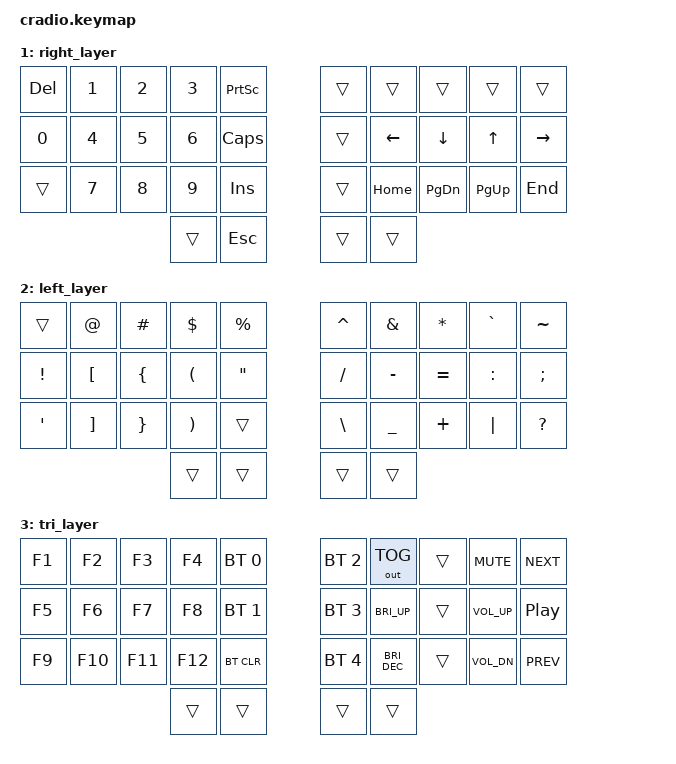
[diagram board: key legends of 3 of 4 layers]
// Copyright (c) 2022 The ZMK Contributors
// SPDX-License-Identifier: MIT

#include <behaviors.dtsi>
#include <dt-bindings/zmk/keys.h>
#include <dt-bindings/zmk/bt.h>
#include <dt-bindings/zmk/outputs.h>

// Home row mods macro
#define HRML(k2,k3,k4) &ht LALT k2  &ht LCTRL k3  &ht LGUI k4
#define HRMR(k1,k2,k3) &ht RGUI k1  &ht RCTRL k2  &ht RALT k3
#define WHRML(k2,k3,k4,k5) &ht LSHFT k2  &ht LALT k3  &ht LCTRL k4 &ht LGUI k5
#define WHRMR(k1,k2,k3,k4) &ht RGUI k1 &ht RCTRL k2  &ht RALT k3  &ht RSHFT k4

#define WIN 0
#define RIG 1
#define LEF 2
#define TRI 3

/* &kscan0 { */
/*     input-gpios */
/*         = <&gpio0 6  (GPIO_ACTIVE_LOW | GPIO_PULL_UP)> */
/*         , <&gpio0 20 (GPIO_ACTIVE_LOW | GPIO_PULL_UP)> */
/*         , <&gpio1 0  (GPIO_ACTIVE_LOW | GPIO_PULL_UP)> */
/*         , <&gpio1 13 (GPIO_ACTIVE_LOW | GPIO_PULL_UP)> */
/*         , <&gpio0 31 (GPIO_ACTIVE_LOW | GPIO_PULL_UP)> */
/*         , <&gpio0 8  (GPIO_ACTIVE_LOW | GPIO_PULL_UP)> */
/*         , <&gpio0 22 (GPIO_ACTIVE_LOW | GPIO_PULL_UP)> */
/*         , <&gpio1 4  (GPIO_ACTIVE_LOW | GPIO_PULL_UP)> */
/*         , <&gpio1 15 (GPIO_ACTIVE_LOW | GPIO_PULL_UP)> */
/*         , <&gpio0 4  (GPIO_ACTIVE_LOW | GPIO_PULL_UP)> */
/*         , <&gpio0 17 (GPIO_ACTIVE_LOW | GPIO_PULL_UP)> */
/*         , <&gpio0 24 (GPIO_ACTIVE_LOW | GPIO_PULL_UP)> */
/*         , <&gpio1 6  (GPIO_ACTIVE_LOW | GPIO_PULL_UP)> */
/*         , <&gpio0 2  (GPIO_ACTIVE_LOW | GPIO_PULL_UP)> */
/*         , <&gpio0 5  (GPIO_ACTIVE_LOW | GPIO_PULL_UP)> */
/*         , <&gpio0 26 (GPIO_ACTIVE_LOW | GPIO_PULL_UP)> */
/*         , <&gpio0 27 (GPIO_ACTIVE_LOW | GPIO_PULL_UP)> */
/*         ; */
/* }; */

/ {
    behaviors {
        ht: hold_tap {
            label = "hold_tap";
            compatible = "zmk,behavior-hold-tap";
            #binding-cells = <2>;
            flavor = "tap-preferred";
            tapping-term-ms = <220>;
            quick-tap-ms = <150>;
            global-quick-tap;
            bindings = <&kp>, <&kp>;
        };
    };

    conditional_layers {
        compatible = "zmk,conditional-layers";
        tri_layer {
            if-layers = <RIG LEF>;
            then-layer = <TRI>;
        };
    };

    keymap {
        compatible = "zmk,keymap";
        default_layer {
            bindings = <
        //╭──────────┬──────────┬──────────┬──────────┬──────────╮   ╭──────────┬──────────┬──────────┬──────────┬──────────╮
        //│  Q       │  W       │  F       │  P       │  B       │   │  J       │  L       │  U       │  Y       │  ;       │
            &kp Q      &kp W      &kp F      &kp P      &kp B          &kp J      &kp L      &kp U      &kp Y      &kp SEMI
        //├──────────┼──────────┼──────────┼──────────┼──────────┤   ├──────────┼──────────┼──────────┼──────────┼──────────┤
        //│  A       │  R (SHFT)│  S (ALT) │  T (CTRL)│  G (WIN) │   │  M (WIN) │  N (CTRL)│  E (ALT) │  I (SHFT)|  O       │
         &kp A    WHRML(R,         S,         T,         G)       WHRMR(M,         N,         E,         I)     &kp O
        //├──────────┼──────────┼──────────┼──────────┼──────────┤   ├──────────┼──────────┼──────────┼──────────┼──────────┤
        //│  Z       │  X       │  C       │  D       │  V       │   │  K       │  H       │ , <      │ . >      │ /        │
            &kp Z      &kp X      &kp C      &kp D      &kp V          &kp K      &kp H      &kp COMMA  &kp DOT    &kp FSLH
        //╰──────────┴──────────┴──────────┼──────────┼──────────┤   ├──────────┼──────────┼──────────┴──────────┴──────────╯
                                            &kp TAB  &lt LEF SPACE   &lt RIG BSPC &kp ENTER
        //                                 ╰──────────┴──────────╯   ╰──────────┴──────────╯
            >;
        };

        right_layer {
            bindings = <
        //╭──────────┬──────────┬──────────┬──────────┬──────────╮   ╭──────────┬──────────┬──────────┬──────────┬──────────╮
        //│   DEL    │  1       │  2       │  3       │  PRTSCR  │   │          │          │          │          │          │
            &kp DEL    &kp N1     &kp N2     &kp N3     &kp PSCRN       &trans     &trans     &trans     &trans    &trans
        //├──────────┼──────────┼──────────┼──────────┼──────────┤   ├──────────┼──────────┼──────────┼──────────┼──────────┤
        //│    0     │ 4        │ 5        │ 6        │   CAPS   |   |          │ LEFT     │ DOWN     │ UP       │ RIGHT    │
            &kp N0     &kp N4     &kp N5     &kp N6     &kp CAPS        &trans    &kp LEFT   &kp DOWN   &kp UP     &kp RIGHT 
        //├──────────┼──────────┼──────────┼──────────┼──────────┤   ├──────────┼──────────┼──────────┼──────────┼──────────┤
        //│          │ 9        │ 8        │ 7        │  INSERT  │   │          │ HOME     │ PAGE DN  │ PAGE UP  │ END      │
            &trans     &kp N7     &kp N8     &kp N9      &kp INS        &trans    &kp HOME   &kp PG_DN  &kp PG_UP  &kp END 
        //╰──────────┴──────────┴──────────┼──────────┼──────────┤   ├──────────┼──────────┼──────────┴──────────┴──────────╯
                                              &trans     &kp ESC        &trans     &trans
        //                                 ╰──────────┴──────────╯   ╰──────────┴──────────╯
            >;
        };

        left_layer {
            bindings = <
        //╭──────────┬──────────┬──────────┬──────────┬──────────╮   ╭──────────┬──────────┬──────────┬──────────┬──────────╮
        //│          │  @       │  #       │  $       │  %       │   │  ^       │  &       │  *       │  `       │  ~       │
            &trans   &kp AT     &kp HASH   &kp DLLR   &kp PRCNT      &kp CARET  &kp AMPS   &kp ASTRK  &kp GRAVE   &kp TILDE
        //├──────────┼──────────┼──────────┼──────────┼──────────┤   ├──────────┼──────────┼──────────┼──────────┼──────────┤
        //│  !       │  [       │  {       │  (       │  "       │   │   /      │  -       │  =       │     :    │  ;       │
            &kp EXCL  &kp LBKT   &kp LBRC   &kp LPAR      &kp DQT     &kp FSLH   &kp MINUS  &kp EQUAL  &kp COLON &kp SEMICOLON
        //├──────────┼──────────┼──────────┼──────────┼──────────┤   ├──────────┼──────────┼──────────┼──────────┼──────────┤
        //│  '       │  ]       │  }       │  )       │          │   │    \     │  _       │  +       │  │       │   ?      │
            &kp SQT     &kp RBKT   &kp RBRC   &kp RPAR   &trans         &kp BSLH   &kp UNDER  &kp PLUS   &kp PIPE  &kp QMARK
        //╰──────────┴──────────┴──────────┼──────────┼──────────┤   ├──────────┼──────────┼──────────┴──────────┴──────────╯
                                             &trans     &trans         &trans     &trans
        //                                 ╰──────────┴──────────╯   ╰──────────┴──────────╯
            >;
        };

        tri_layer {
            bindings = <
        //╭──────────┬──────────┬──────────┬───────────┬────────────╮   ╭────────────┬────────────┬──────────┬───────────┬──────────╮
        //│  F1      │  F2      │  F3      │  F4       │ PROFILE 0  │   │ PROFILE 2  │ TOGGLEOUT  │          │ VOL MUTE  │ NEXTSONG │
            &kp F1     &kp F2     &kp F3     &kp F4     &bt BT_SEL 0     &bt BT_SEL 2  &out OUT_TOG  &trans   &kp C_MUTE  &kp C_NEXT
        //├──────────┼──────────┼──────────┼───────────┼────────────┤   ├────────────┼────────────┼──────────┼───────────┼──────────┤
        //│  F5      │  F6      │  F7      │  F8       │ PROFILE 1  │   │ PROFILE 3  │ INC BRIGHT │          │  VOL UP   │PAUSEMUSIC│
            &kp F5     &kp F6     &kp F7     &kp F8     &bt BT_SEL 1     &bt BT_SEL 3  &kp C_BRI_UP  &trans   &kp C_VOL_UP  &kp C_PP
        //├──────────┼──────────┼──────────┼───────────┼────────────┤   ├────────────┼────────────┼──────────┼───────────┼──────────┤
        //│  F9      │  F10     │  F11     │  F12      │  CLEAR BT  │   │ PROFILE 4  │ DEC BRIGHT │          |  VOL DOWN │ PREVSONG │
            &kp F9     &kp F10    &kp F11    &kp F12     &bt BT_CLR      &bt BT_SEL 4  &kp C_BRI_DEC &trans   &kp C_VOL_DN &kp C_PREV
        //╰──────────┴──────────┴──────────┼───────────┼────────────┤   ├────────────┼────────────┼──────────┴───────────┴──────────╯
                                                &trans     &trans         &trans     &trans
        //                                  ╰───────────┴──────────╯   ╰──────────┴────────────╯
            >;
        };
    };
};
